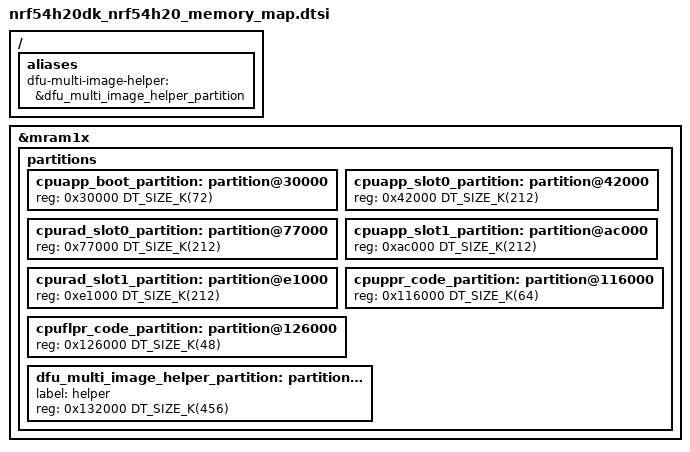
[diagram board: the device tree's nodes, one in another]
/*
 * Copyright (c) 2025 Nordic Semiconductor ASA
 *
 * SPDX-License-Identifier: LicenseRef-Nordic-5-Clause
 */

/delete-node/ &cpuapp_boot_partition;
/delete-node/ &cpuapp_slot0_partition;
/delete-node/ &cpuapp_slot1_partition;
/delete-node/ &cpurad_slot0_partition;
/delete-node/ &cpurad_slot1_partition;
/delete-node/ &cpuppr_code_partition;
/delete-node/ &cpuflpr_code_partition;

/ {
	aliases {
		dfu-multi-image-helper = &dfu_multi_image_helper_partition;
	};
};

&mram1x {
	partitions {
		cpuapp_boot_partition: partition@30000 {
			reg = <0x30000 DT_SIZE_K(72)>;
		};

		cpuapp_slot0_partition: partition@42000 {
			reg = <0x42000 DT_SIZE_K(212)>;
		};

		cpurad_slot0_partition: partition@77000 {
			reg = <0x77000 DT_SIZE_K(212)>;
		};

		cpuapp_slot1_partition: partition@ac000 {
			reg = <0xac000 DT_SIZE_K(212)>;
		};

		cpurad_slot1_partition: partition@e1000 {
			reg = <0xe1000 DT_SIZE_K(212)>;
		};

		cpuppr_code_partition: partition@116000 {
			reg = <0x116000 DT_SIZE_K(64)>;
		};

		cpuflpr_code_partition: partition@126000 {
			reg = <0x126000 DT_SIZE_K(48)>;
		};

		dfu_multi_image_helper_partition: partition@132000 {
			label = "helper";
			reg = <0x132000 DT_SIZE_K(456)>;
		};
	};
};
